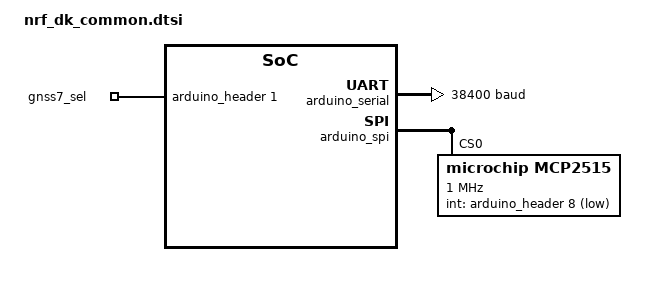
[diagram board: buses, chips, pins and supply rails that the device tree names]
/*
 * Copyright (c) 2023 Golioth, Inc.
 *
 * SPDX-License-Identifier: Apache-2.0
 */

 / {
	chosen {
		zephyr,canbus = &mcp2515;
	};

	aliases {
		click-uart = &arduino_serial;
		click-i2c = &arduino_i2c;
		gnss7-sel = &gnss7_sel;
	};

	gpio_logic {
		compatible = "gpio-leds";
		gnss7_sel: gnss7_sel {
			gpios = <&arduino_header 1 GPIO_ACTIVE_HIGH>; /* A1 */
		};
	};
};

&arduino_serial {
	status = "okay";
	current-speed = <38400>;
};

&arduino_i2c {
	/* Needed for I2C writes used by libostentus */
	zephyr,concat-buf-size = <48>;
};

&arduino_spi {
	status = "okay";

	mcp2515: mcp2515@0 {
		compatible = "microchip,mcp2515";
		spi-max-frequency = <1000000>;
		int-gpios = <&arduino_header 8 GPIO_ACTIVE_LOW>; /* D2 */
		status = "okay";
		reg = <0x0>;
		osc-freq = <10000000>;
		bus-speed = <500000>;
		sjw = <1>;
		sample-point = <875>;

		can-transceiver {
			max-bitrate = <1000000>;
		};
	};
};
